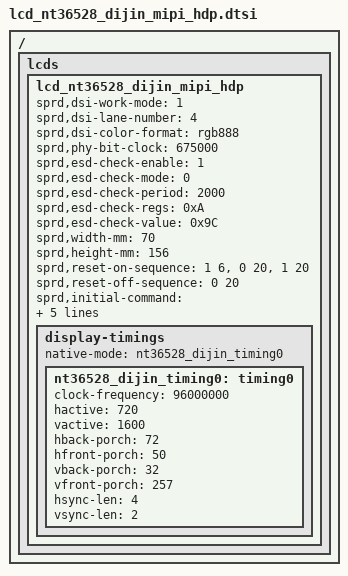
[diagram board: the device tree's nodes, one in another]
/*
 * nt36528 dijin LCD config dtsi file for spreadtrum
 *
 * Copyright (C) 2018, Spreadtrum Communications Inc.
 *
 * SPDX-License-Identifier: (GPL-2.0+ OR MIT)
 */

/ {
	fragment {
		target-path = "/";
		__overlay__ {
			lcds {
				lcd_nt36528_dijin_mipi_hdp: lcd_nt36528_dijin_mipi_hdp {

					sprd,dsi-work-mode = <1>; /* video burst mode*/
					sprd,dsi-lane-number = <4>;
					sprd,dsi-color-format = "rgb888";


					sprd,phy-bit-clock = <675000>;	/* kbps */
//					sprd,phy-escape-clock = <20000>;/* kHz */

					sprd,esd-check-enable = <1>;
					sprd,esd-check-mode = <0>;		//1: te_check
					sprd,esd-check-period = <2000>;
					sprd,esd-check-regs = <0xA>;
					sprd,esd-check-value = <0x9C>;
					
					sprd,width-mm = <70>;
					sprd,height-mm = <156>;
					
					sprd,reset-on-sequence = <1 6>, <0 20>, <1 20>;
					sprd,reset-off-sequence = <0 20>;

//					sprd,use-dcs-write;

					sprd,initial-command = [
/*
						////////////////1. GOA & POWER RELATED////////////////
						15 01 00 02 FF 20
						15 00 00 02 FB 01
						15 00 00 02 07 B4
						15 00 00 02 08 B4
						15 00 00 02 0D 80
						15 00 00 02 1F 33
						15 00 00 02 94 C0
						15 00 00 02 95 0E
						15 00 00 02 96 0E
						15 01 00 02 FF 24
						15 00 00 02 FB 01
						15 00 00 02 00 26
						15 00 00 02 01 26
						15 00 00 02 02 08
						15 00 00 02 03 05
						15 00 00 02 04 1C
						15 00 00 02 05 1D
						15 00 00 02 06 0C
						15 00 00 02 07 0D
						15 00 00 02 08 0E
						15 00 00 02 09 0F
						15 00 00 02 0A 10
						15 00 00 02 0B 11
						15 00 00 02 0C 12
						15 00 00 02 0D 13
						15 00 00 02 0E 04
						15 00 00 02 0F 03
						15 00 00 02 10 03
						15 00 00 02 11 03
						15 00 00 02 12 03
						15 00 00 02 13 03
						15 00 00 02 14 03
						15 00 00 02 15 03
						15 00 00 02 16 26
						15 00 00 02 17 26
						15 00 00 02 18 08
						15 00 00 02 19 05
						15 00 00 02 1A 1C
						15 00 00 02 1B 1D
						15 00 00 02 1C 0C
						15 00 00 02 1D 0D
						15 00 00 02 1E 0E
						15 00 00 02 1F 0F
						15 00 00 02 20 10
						15 00 00 02 21 11
						15 00 00 02 22 12
						15 00 00 02 23 13
						15 00 00 02 24 04
						15 00 00 02 25 03
						15 00 00 02 26 03
						15 00 00 02 27 03
						15 00 00 02 28 03
						15 00 00 02 29 03
						15 00 00 02 2A 03
						15 00 00 02 2B 03
						15 00 00 02 2F 06
						15 00 00 02 34 06
						15 00 00 02 3A 05
						15 00 00 02 3B A9
						15 00 00 02 3D 52
						15 00 00 02 3F 43
						15 00 00 02 43 08
						15 00 00 02 4A 05
						15 00 00 02 4B A9
						15 00 00 02 4C 51
						15 00 00 02 50 87
						15 00 00 02 51 78
						15 00 00 02 52 56
						15 00 00 02 53 34
						15 00 00 02 54 12
						39 00 00 03 55 43 03
						15 00 00 02 56 08
						15 00 00 02 5C 08
						15 00 00 02 5D 0A
						39 00 00 03 5E 00 10
						15 00 00 02 7E 20
						15 00 00 02 C4 11
						15 00 00 02 C5 03
						15 00 00 02 C6 99
						15 00 00 02 C7 08
						15 00 00 02 C8 07
						15 00 00 02 C9 08
						15 00 00 02 CA 07
						15 01 00 02 FF 25
						15 00 00 02 FB 01
						15 00 00 02 44 05
						15 00 00 02 45 A9
						15 00 00 02 46 05
						15 00 00 02 47 A9
						15 00 00 02 5D 05
						15 00 00 02 5E A9
						15 00 00 02 5F 05
						15 00 00 02 60 A9
						15 00 00 02 C0 04
						15 01 00 02 FF 26
						15 00 00 02 FB 01
						15 00 00 02 4E A9
						15 00 00 02 50 A9
						15 00 00 02 6F A9
						15 00 00 02 71 A9
						15 00 00 02 7C A9
						15 00 00 02 7F A9
						15 01 00 02 FF 27
						15 00 00 02 FB 01
						15 00 00 02 15 D8
						15 00 00 02 78 84
						15 00 00 02 79 03
						15 00 00 02 7A 03
						15 00 00 02 7C 05
						15 00 00 02 7D A9
						15 00 00 02 83 06
						15 00 00 02 84 32
						15 00 00 02 87 32
						15 00 00 02 88 06
						15 00 00 02 8B 43
						15 00 00 02 8C 04
						15 00 00 02 8D 05
						15 00 00 02 8E 06
						15 00 00 02 8F 07
						15 00 00 02 90 08
						15 00 00 02 91 09
						15 00 00 02 92 0A
						15 00 00 02 93 44
						15 00 00 02 94 44
						15 00 00 02 96 0B
						15 00 00 02 97 15
						15 00 00 02 98 88
						15 00 00 02 99 7F
						15 00 00 02 B4 10
						15 00 00 02 C4 05
						15 00 00 02 C5 A9
						15 00 00 02 C8 05
						15 00 00 02 C9 A9
						15 00 00 02 E4 00
						15 00 00 02 E5 9D
						15 01 00 02 FF 2A
						15 00 00 02 FB 01
						15 00 00 02 64 96
						15 00 00 02 67 96
						15 00 00 02 6A 96
						15 00 00 02 70 92
						15 00 00 02 7F 96
						15 00 00 02 A2 3F
						15 00 00 02 A3 F0
						15 00 00 02 A4 03
						////////////////2. TIMING RELATED////////////////
						15 00 00 02 FF 23
						15 00 00 02 FB 01
						15 00 00 02 11 00
						15 00 00 02 12 B4
						15 00 00 02 15 E9
						15 00 00 02 16 14
						15 01 00 02 FF 24
						15 00 00 02 FB 01
						15 00 00 02 5A 0A
						15 00 00 02 5B 86
						15 00 00 02 92 CA
						39 00 00 03 93 01 01
						15 00 00 02 DC C5
						15 00 00 02 E0 C5
						15 00 00 02 E2 C5
						15 00 00 02 E4 C5
						15 00 00 02 E6 C5
						15 00 00 02 EA C5
						15 00 00 02 EE C5
						15 00 00 02 F0 C5
						15 01 00 02 FF 25
						15 00 00 02 FB 01
						39 00 00 04 02 00 00 41
						15 00 00 02 13 02
						15 00 00 02 14 66
						15 00 00 02 15 02
						15 00 00 02 16 C3
						15 00 00 02 1F 0A
						15 00 00 02 20 86
						15 00 00 02 26 0A
						15 00 00 02 27 86
						15 00 00 02 40 00
						15 00 00 02 48 0A
						15 00 00 02 49 86
						15 00 00 02 50 0A
						15 00 00 02 51 86
						15 00 00 02 61 0A
						15 00 00 02 62 86
						15 00 00 02 68 10
						15 01 00 02 FF 26
						15 00 00 02 FB 01
						15 00 00 02 00 80
						15 00 00 02 04 2F
						15 00 00 02 0A 05
						15 00 00 02 19 0B
						15 00 00 02 1A 54
						15 00 00 02 1B 0A
						15 00 00 02 1C C9
						15 00 00 02 1E CA
						15 00 00 02 1F CA
						15 00 00 02 24 00
						15 00 00 02 25 CA
						15 00 00 02 2A 0B
						15 00 00 02 2B 54
						15 00 00 02 2F 00
						15 00 00 02 30 CA
						15 00 00 02 32 CA
						15 00 00 02 37 11
						15 00 00 02 38 01
						15 00 00 02 39 10
						15 00 00 02 3A CA
						15 00 00 02 40 BF
						15 00 00 02 41 BF
						15 00 00 02 42 BF
						15 00 00 02 44 BF
						15 00 00 02 45 07
						15 00 00 02 46 BF
						15 00 00 02 48 BF
						15 00 00 02 4A BF
						15 00 00 02 52 A9
						15 00 00 02 58 A9
						15 00 00 02 5C A9
						15 00 00 02 60 05
						15 00 00 02 61 A9
						15 00 00 02 64 05
						15 00 00 02 65 A9
						15 00 00 02 69 05
						15 00 00 02 6A A9
						15 00 00 02 73 A9
						15 00 00 02 8B 35
						15 00 00 02 8C 09
						15 00 00 02 8D 00
						15 00 00 02 99 0B
						15 00 00 02 9A 54
						15 00 00 02 9B 0A
						15 00 00 02 9C C9
						15 00 00 02 9D 0B
						15 00 00 02 9E 54
						15 00 00 02 C3 00
						15 00 00 02 CB 0A
						15 00 00 02 D6 9C
						15 00 00 02 D7 9E
						15 00 00 02 D8 A0
						15 00 00 02 D9 A2
						15 00 00 02 DA A4
						15 00 00 02 DB A6
						15 00 00 02 DC A8
						15 00 00 02 DD AA
						15 01 00 02 FF 27
						15 00 00 02 FB 01
						15 00 00 02 58 AC
						39 00 00 03 59 00 0B
						39 00 00 03 5A 00 01
						39 00 00 03 5D 00 01
						39 00 00 03 5E 00 F4
						15 00 00 02 5F 01
						39 00 00 03 60 06 5A
						15 00 00 02 C0 08
						15 00 00 02 EF 08
						15 00 00 02 F4 05
						15 01 00 02 FF 2A
						15 00 00 02 FB 01
						15 00 00 02 04 BA
						15 00 00 02 06 BA
						15 00 00 02 09 BA
						15 00 00 02 0B BA
						15 00 00 02 0D BA
						15 00 00 02 14 BA
						15 00 00 02 15 BA
						15 00 00 02 16 BA
						15 00 00 02 23 08
						15 00 00 02 27 01
						15 00 00 02 28 33
						15 00 00 02 2B 01
						15 00 00 02 2D 33
						15 00 00 02 33 0A
						15 00 00 02 35 0A
						15 00 00 02 37 0A
						15 00 00 02 99 95
						15 00 00 02 9A 0B
						15 00 00 02 AD 3C
						15 00 00 02 AE 7D
						15 00 00 02 AF 43
						15 00 00 02 B0 18
						15 00 00 02 B3 66
						15 00 00 02 FF 10
						15 00 00 02 FB 01
						*/
//						15 00 00 02 35 00
						15 78 00 02 11 00
						15 30 00 02 29 00
					];

					sprd,sleep-in-command = [
					  05 0A 00 01 28
					  05 78 00 01 10
						];

					sprd,sleep-out-command = [
					  05 78 00 01 11
					  05 30 00 01 29
					];

					display-timings {
						native-mode = <&nt36528_dijin_timing0>;

						nt36528_dijin_timing0: timing0 {
							clock-frequency = <96000000>;
						  hactive = <720>;
						  vactive = <1600>;
						  hback-porch = <72>;
						  hfront-porch = <50>;
						  vback-porch = <32>;
						  vfront-porch = <257>;
						  hsync-len = <4>;
						  vsync-len = <2>;
						};
					};
				};
			};
		};
	};
};
